VERSION ""

NS_ :

BS_:

BU_: SuspForceCtrlRR SuspForceCtrlRL SuspForceCtrlFR SuspForceCtrlFL SuspCtrl VehSim

BO_ 5 Susp_Defl_RR: 2 VehSim
 SG_ Susp_Ctrl_SuspDefl_RR : 0|16@1+ (1.8006662465112E-005,-1.1800666246511) [-1.1800666246511|-2.2204460492503E-016] "m"  SuspCtrl

BO_ 4 Susp_Defl_RL: 2 VehSim
 SG_ Susp_Ctrl_SuspDefl_RL : 0|16@1+ (1.8006662465112E-005,-1.1800666246511) [-1.1800666246511|-2.2204460492503E-016] "m"  SuspCtrl

BO_ 3 Susp_Defl_FR: 2 VehSim
 SG_ Susp_Ctrl_SuspDefl_FR : 0|16@1+ (1.8006662465112E-005,-1.1800666246511) [-1.1800666246511|-2.2204460492503E-016] "m"  SuspCtrl

BO_ 2 Susp_Defl_FL: 2 VehSim
 SG_ Susp_Ctrl_SuspDefl_FL : 0|16@1+ (1.8006662465112E-005,-1.1800666246511) [-1.1800666246511|-2.2204460492503E-016] "m"  SuspCtrl

BO_ 7 Gearbox_State: 1 VehSim
 SG_ Trms_Gear : 0|3@1+ (1,0) [0|7] "-" Vector__XXX

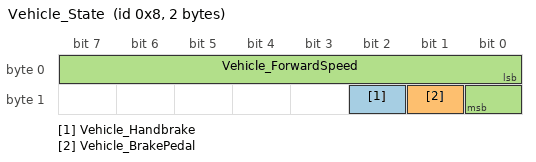
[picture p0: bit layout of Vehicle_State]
BO_ 8 Vehicle_State: 2 VehSim
 SG_ Vehicle_Handbrake : 10|1@1+ (1,0) [0|1] "-"  SuspCtrl
 SG_ Vehicle_BrakePedal : 9|1@1+ (1,0) [0|1] "-"  SuspCtrl
 SG_ Vehicle_ForwardSpeed : 0|9@1+ (0.71428571428571,-60) [-60|305] "m/s"  SuspCtrl

BO_ 6 Eng_State: 3 VehSim
 SG_ Eng_Throttle : 16|8@1+ (0.003921568627451,0) [0|1] "-"  SuspCtrl
 SG_ Eng_RPM : 0|13@1+ (1,0) [0|8191] "1/min"  SuspCtrl

BO_ 1 Susp_ActForces_R: 8 SuspCtrl
 SG_ Susp_Ctrl_DesiredForce_RR : 32|32@1- (2.7944357195951E-006,1) [-6000.0050132177|6002.0050104232] "N"  SuspForceCtrlRR,VehSim
 SG_ Susp_Ctrl_DesiredForce_RL : 0|32@1- (2.7944357195951E-006,1) [-6000.0050132177|6002.0050104232] "N"  SuspForceCtrlRL,VehSim

BO_ 0 Susp_ActForces_F: 8 SuspCtrl
 SG_ Susp_Ctrl_DesiredForce_FR : 32|32@1- (2.7944357195951E-006,1) [-6000.0050132177|6002.0050104232] "N"  SuspForceCtrlFR,VehSim
 SG_ Susp_Ctrl_DesiredForce_FL : 0|32@1- (2.7944357195951E-006,1) [-6000.0050132177|6002.0050104232] "N"  SuspForceCtrlFL,VehSim

EV_ EnvKlemme15: 0 [0|1] "" 0 1 DUMMY_NODE_VECTOR0 Vector__XXX;

BA_DEF_ BO_  "GenMsgILSupport" ENUM  "No","Yes";
BA_DEF_ BU_  "NmStationAddress" INT 0 63;
BA_DEF_  "NmBaseAddress" HEX 1024 1087;
BA_DEF_  "BusType" STRING ;
BA_DEF_ BO_  "GenMsgCycleTime" INT 0 50000;
BA_DEF_ BO_  "GenMsgSendType" ENUM  "Cyclic","NotUsed","NotUsed","NotUsed","NotUsed","Cyclic","NotUsed","IfActive","NoMsgSendType","NotUsed","vector_leerstring";
BA_DEF_ SG_  "GenSigSendType" ENUM  "Cyclic","OnWrite","OnWriteWithRepetition","OnChange","OnChangeWithRepetition","IfActive","IfActiveWithRepetition","NoSigSendType","NotUsed","NotUsed","NotUsed","NotUsed","NotUsed";
BA_DEF_ SG_  "GenSigStartValue" FLOAT 0 100000000000;
BA_DEF_DEF_  "GenMsgILSupport" "Yes";
BA_DEF_DEF_  "NmStationAddress" 0;
BA_DEF_DEF_  "NmBaseAddress" 1024;
BA_DEF_DEF_  "BusType" "CAN";
BA_DEF_DEF_  "GenMsgCycleTime" 2;
BA_DEF_DEF_  "GenMsgSendType" "NoMsgSendType";
BA_DEF_DEF_  "GenSigSendType" "Cyclic";
BA_DEF_DEF_  "GenSigStartValue" 0;
BA_ "NmStationAddress" BU_ SuspForceCtrlRR 5;
BA_ "NmStationAddress" BU_ SuspForceCtrlRL 4;
BA_ "NmStationAddress" BU_ SuspForceCtrlFR 3;
BA_ "NmStationAddress" BU_ SuspForceCtrlFL 2;
BA_ "NmStationAddress" BU_ SuspCtrl 1;
BA_ "GenMsgCycleTime" BO_ 5 5;
BA_ "GenMsgCycleTime" BO_ 4 5;
BA_ "GenMsgCycleTime" BO_ 3 5;
BA_ "GenMsgCycleTime" BO_ 2 5;
BA_ "GenMsgCycleTime" BO_ 7 200;
BA_ "GenMsgCycleTime" BO_ 8 500;
BA_ "GenMsgCycleTime" BO_ 6 150;
BA_ "GenMsgCycleTime" BO_ 1 5;
BA_ "GenMsgCycleTime" BO_ 0 5;
BA_ "GenSigStartValue" SG_ 5 Susp_Ctrl_SuspDefl_RR 37767.5;
BA_ "GenSigStartValue" SG_ 4 Susp_Ctrl_SuspDefl_RL 37767.5;
BA_ "GenSigStartValue" SG_ 3 Susp_Ctrl_SuspDefl_FR 37767.5;
BA_ "GenSigStartValue" SG_ 2 Susp_Ctrl_SuspDefl_FL 37767.5;
BA_ "GenSigStartValue" SG_ 8 Vehicle_ForwardSpeed 84;
